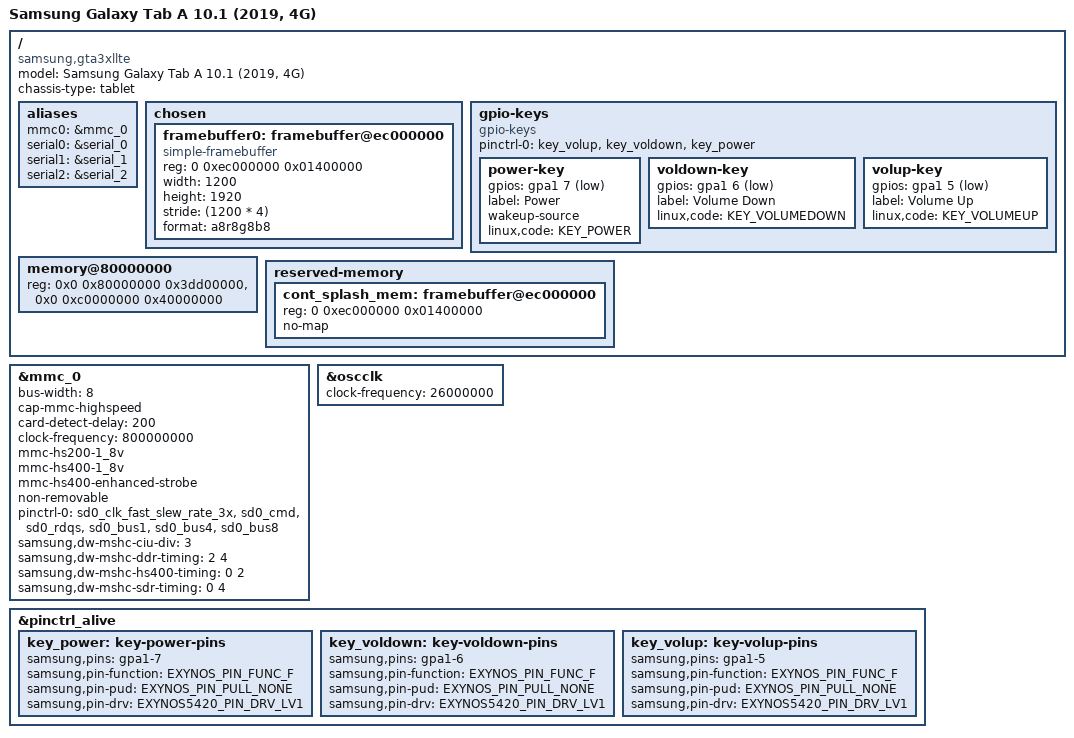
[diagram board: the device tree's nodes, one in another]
// SPDX-License-Identifier: GPL-2.0
/*
 * Samsung Galaxy Tab A 10.1 (2019, 4G) (gta3xllte/SM-T515) device tree source
 *
 * Copyright (c) 2026, Umer Uddin <umer.uddin@mentallysanemainliners.org>
 */

/dts-v1/;
#include "exynos7885.dtsi"
#include <dt-bindings/gpio/gpio.h>
#include <dt-bindings/input/input.h>

/ {
	model = "Samsung Galaxy Tab A 10.1 (2019, 4G)";
	compatible = "samsung,gta3xllte", "samsung,exynos7885";
	chassis-type = "tablet";

	aliases {
		mmc0 = &mmc_0;
		serial0 = &serial_0;
		serial1 = &serial_1;
		serial2 = &serial_2;
	};

	chosen {
		ranges;
		#address-cells = <2>;
		#size-cells = <1>;

		framebuffer0: framebuffer@ec000000 {
			compatible = "simple-framebuffer";
			reg = <0 0xec000000 0x01400000>;
			width = <1200>;
			height = <1920>;
			stride = <(1200 * 4)>;
			format = "a8r8g8b8";
		};
	};

	gpio-keys {
		compatible = "gpio-keys";
		pinctrl-0 = <&key_volup &key_voldown &key_power>;
		pinctrl-names = "default";

		power-key {
			gpios = <&gpa1 7 GPIO_ACTIVE_LOW>;
			label = "Power";
			wakeup-source;
			linux,code = <KEY_POWER>;
		};

		voldown-key {
			gpios = <&gpa1 6 GPIO_ACTIVE_LOW>;
			label = "Volume Down";
			linux,code = <KEY_VOLUMEDOWN>;
		};

		volup-key {
			gpios = <&gpa1 5 GPIO_ACTIVE_LOW>;
			label = "Volume Up";
			linux,code = <KEY_VOLUMEUP>;
		};
	};

	memory@80000000 {
		device_type = "memory";
		reg = <0x0 0x80000000 0x3dd00000>,
		      <0x0 0xc0000000 0x40000000>;
	};

	reserved-memory {
		ranges;
		#address-cells = <2>;
		#size-cells = <1>;

		cont_splash_mem: framebuffer@ec000000 {
			reg = <0 0xec000000 0x01400000>;
			no-map;
		};
	};
};

&mmc_0 {
	bus-width = <8>;
	cap-mmc-highspeed;
	card-detect-delay = <200>;
	clock-frequency = <800000000>;
	mmc-hs200-1_8v;
	mmc-hs400-1_8v;
	mmc-hs400-enhanced-strobe;
	non-removable;
	pinctrl-0 = <&sd0_clk_fast_slew_rate_3x &sd0_cmd &sd0_rdqs
		     &sd0_bus1 &sd0_bus4 &sd0_bus8>;
	pinctrl-names = "default";

	samsung,dw-mshc-ciu-div = <3>;
	samsung,dw-mshc-ddr-timing = <2 4>;
	samsung,dw-mshc-hs400-timing = <0 2>;
	samsung,dw-mshc-sdr-timing = <0 4>;

	status = "okay";
};

&oscclk {
	clock-frequency = <26000000>;
};

&pinctrl_alive {
	key_power: key-power-pins {
		samsung,pins = "gpa1-7";
		samsung,pin-function = <EXYNOS_PIN_FUNC_F>;
		samsung,pin-pud = <EXYNOS_PIN_PULL_NONE>;
		samsung,pin-drv = <EXYNOS5420_PIN_DRV_LV1>;
	};

	key_voldown: key-voldown-pins {
		samsung,pins = "gpa1-6";
		samsung,pin-function = <EXYNOS_PIN_FUNC_F>;
		samsung,pin-pud = <EXYNOS_PIN_PULL_NONE>;
		samsung,pin-drv = <EXYNOS5420_PIN_DRV_LV1>;
	};

	key_volup: key-volup-pins {
		samsung,pins = "gpa1-5";
		samsung,pin-function = <EXYNOS_PIN_FUNC_F>;
		samsung,pin-pud = <EXYNOS_PIN_PULL_NONE>;
		samsung,pin-drv = <EXYNOS5420_PIN_DRV_LV1>;
	};
};
